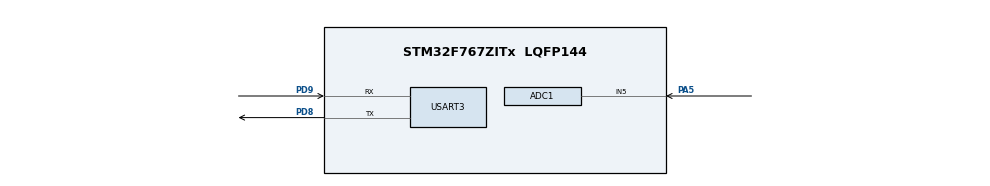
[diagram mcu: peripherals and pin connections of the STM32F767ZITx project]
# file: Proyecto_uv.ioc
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ADC1.Channel-2\#ChannelRegularConversion=ADC_CHANNEL_5
ADC1.NbrOfConversionFlag=1
ADC1.Rank-2\#ChannelRegularConversion=1
ADC1.SamplingTime-2\#ChannelRegularConversion=ADC_SAMPLETIME_3CYCLES
ADC1.master=1
Dma.Request0=USART3_TX
Dma.USART3_TX.0.Direction=DMA_MEMORY_TO_PERIPH
Dma.USART3_TX.0.FIFOMode=DMA_FIFOMODE_DISABLE
Dma.USART3_TX.0.Instance=DMA1_Stream3
Dma.USART3_TX.0.MemDataAlignment=DMA_MDATAALIGN_BYTE
Dma.USART3_TX.0.MemInc=DMA_MINC_ENABLE
Dma.USART3_TX.0.Mode=DMA_NORMAL
Dma.USART3_TX.0.PeriphDataAlignment=DMA_PDATAALIGN_BYTE
Dma.USART3_TX.0.PeriphInc=DMA_PINC_DISABLE
Dma.USART3_TX.0.Priority=DMA_PRIORITY_LOW
FREERTOS.Tasks01=defaultTask,24,128,StartDefaultTask,Default,NULL,Dynamic,NULL,NULL
FREERTOS.configUSE_NEWLIB_REENTRANT=1
Mcu.Family=STM32F7
Mcu.Name=STM32F767ZITx
Mcu.Package=LQFP144
NVIC.DMA1_Stream3_IRQn=true\:5\:0\:false\:false\:true\:true\:false\:true\:true
NVIC.PriorityGroup=NVIC_PRIORITYGROUP_4
NVIC.TIM1_UP_TIM10_IRQn=true\:15\:0\:false\:false\:true\:false\:false\:true\:true
NVIC.TimeBase=TIM1_UP_TIM10_IRQn
NVIC.TimeBaseIP=TIM1
PA5.Signal=ADCx_IN5
PD8.Mode=Asynchronous
PD8.Signal=USART3_TX
PD9.Mode=Asynchronous
PD9.Signal=USART3_RX
ProjectManager.HeapSize=0x200
ProjectManager.StackSize=0x400
ProjectManager.TargetToolchain=STM32CubeIDE
RCC.HSE_VALUE=25000000
RCC.HSI_VALUE=16000000
RCC.LSE_VALUE=32768
RCC.USBFreq_Value=96000000
RCC.VCOOutputFreq_Value=192000000
SH.ADCx_IN5.0=ADC1_IN5,IN5
USART3.VirtualMode-Asynchronous=VM_ASYNC
VP_FREERTOS_VS_CMSIS_V2.Mode=CMSIS_V2
VP_SYS_VS_tim1.Mode=TIM1
board=custom

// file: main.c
/* USER CODE BEGIN Header */
/**
 ******************************************************************************
 * @file           : main.c
 * @brief          : Main program body
 ******************************************************************************
 * @attention
 *
 * Copyright (c) 2022 STMicroelectronics.
 * All rights reserved.
 *
 * This software is licensed under terms that can be found in the LICENSE file
 * in the root directory of this software component.
 * If no LICENSE file comes with this software, it is provided AS-IS.
 *
 ******************************************************************************
 */
/* USER CODE END Header */
#include "main.h"
#include "cmsis_os.h"
#include <stdio.h>
#include <string.h>

ADC_HandleTypeDef hadc1;

UART_HandleTypeDef huart3;
DMA_HandleTypeDef hdma_usart3_tx;

/* Definitions for defaultTask */
osThreadId_t defaultTaskHandle;
const osThreadAttr_t defaultTask_attributes = { .name = "defaultTask",
		.stack_size = 128 * 4, .priority = (osPriority_t) osPriorityNormal, };

void SystemClock_Config(void);
static void MX_GPIO_Init(void);
static void MX_ADC1_Init(void);
static void MX_DMA_Init(void);
static void MX_USART3_UART_Init(void);
void StartDefaultTask(void *argument);

int main(void) {
	/* USER CODE BEGIN 1 */
	float sensorVoltage;
	int sensorValue;
	float sensorResult;
	int buffer;
	char array[100];
	HAL_ADC_Start(&hadc1);
	/* USER CODE END 1 */

	/* MCU Configuration--------------------------------------------------------*/

	/* Reset of all peripherals, Initializes the Flash interface and the Systick. */
	HAL_Init();

	/* Configure the system clock */
	SystemClock_Config();

	/* Initialize all configured peripherals */
	MX_GPIO_Init();
	MX_ADC1_Init();
	MX_DMA_Init();
	MX_USART3_UART_Init();
	/* Init scheduler */
	osKernelInitialize();

	/* Create the thread(s) */
	/* creation of defaultTask */
	defaultTaskHandle = osThreadNew(StartDefaultTask, NULL,
			&defaultTask_attributes);

	/* Start scheduler */
	osKernelStart();

	/* We should never get here as control is now taken by the scheduler */
	/* Infinite loop */
	while (1) {
		HAL_ADC_Start(&hadc1);
		HAL_ADC_PollForConversion(&hadc1, 100);
		sensorVoltage = HAL_ADC_GetValue(&hadc1);
		sensorResult = sensorVoltage / 1024 * 5.0;
		sensorValue = (int) sensorResult;
		HAL_ADC_Stop(&hadc1);

		buffer = sprintf(array, "Solar level %d \r\n", sensorValue);
		HAL_UART_Transmit(&huart3, (uint8_t*) &buffer, 50, 100);

		HAL_Delay(100);

	}
}

void SystemClock_Config(void) {
	RCC_OscInitTypeDef RCC_OscInitStruct = { 0 };
	RCC_ClkInitTypeDef RCC_ClkInitStruct = { 0 };

	/** Configure the main internal regulator output voltage
	 */
	__HAL_RCC_PWR_CLK_ENABLE();
	__HAL_PWR_VOLTAGESCALING_CONFIG(PWR_REGULATOR_VOLTAGE_SCALE3);

	/** Initializes the RCC Oscillators according to the specified parameters
	 * in the RCC_OscInitTypeDef structure.
	 */
	RCC_OscInitStruct.OscillatorType = RCC_OSCILLATORTYPE_HSI;
	RCC_OscInitStruct.HSIState = RCC_HSI_ON;
	RCC_OscInitStruct.HSICalibrationValue = RCC_HSICALIBRATION_DEFAULT;
	RCC_OscInitStruct.PLL.PLLState = RCC_PLL_NONE;
	if (HAL_RCC_OscConfig(&RCC_OscInitStruct) != HAL_OK) {
		Error_Handler();
	}

	/** Initializes the CPU, AHB and APB buses clocks
	 */
	RCC_ClkInitStruct.ClockType = RCC_CLOCKTYPE_HCLK | RCC_CLOCKTYPE_SYSCLK
			| RCC_CLOCKTYPE_PCLK1 | RCC_CLOCKTYPE_PCLK2;
	RCC_ClkInitStruct.SYSCLKSource = RCC_SYSCLKSOURCE_HSI;
	RCC_ClkInitStruct.AHBCLKDivider = RCC_SYSCLK_DIV1;
	RCC_ClkInitStruct.APB1CLKDivider = RCC_HCLK_DIV1;
	RCC_ClkInitStruct.APB2CLKDivider = RCC_HCLK_DIV1;

	if (HAL_RCC_ClockConfig(&RCC_ClkInitStruct, FLASH_LATENCY_0) != HAL_OK) {
		Error_Handler();
	}
}

static void MX_ADC1_Init(void) {

	ADC_ChannelConfTypeDef sConfig = { 0 };

	/** Configure the global features of the ADC (Clock, Resolution, Data Alignment and number of conversion)
	 */
	hadc1.Instance = ADC1;
	hadc1.Init.ClockPrescaler = ADC_CLOCK_SYNC_PCLK_DIV2;
	hadc1.Init.Resolution = ADC_RESOLUTION_12B;
	hadc1.Init.ScanConvMode = ADC_SCAN_DISABLE;
	hadc1.Init.ContinuousConvMode = DISABLE;
	hadc1.Init.DiscontinuousConvMode = DISABLE;
	hadc1.Init.ExternalTrigConvEdge = ADC_EXTERNALTRIGCONVEDGE_NONE;
	hadc1.Init.ExternalTrigConv = ADC_SOFTWARE_START;
	hadc1.Init.DataAlign = ADC_DATAALIGN_RIGHT;
	hadc1.Init.NbrOfConversion = 1;
	hadc1.Init.DMAContinuousRequests = DISABLE;
	hadc1.Init.EOCSelection = ADC_EOC_SINGLE_CONV;
	if (HAL_ADC_Init(&hadc1) != HAL_OK) {
		Error_Handler();
	}

	/** Configure for the selected ADC regular channel its corresponding rank in the sequencer and its sample time.
	 */
	sConfig.Channel = ADC_CHANNEL_5;
	sConfig.Rank = ADC_REGULAR_RANK_1;
	sConfig.SamplingTime = ADC_SAMPLETIME_3CYCLES;
	if (HAL_ADC_ConfigChannel(&hadc1, &sConfig) != HAL_OK) {
		Error_Handler();
	}

}

static void MX_USART3_UART_Init(void) {

	huart3.Instance = USART3;
	huart3.Init.BaudRate = 115200;
	huart3.Init.WordLength = UART_WORDLENGTH_8B;
	huart3.Init.StopBits = UART_STOPBITS_1;
	huart3.Init.Parity = UART_PARITY_NONE;
	huart3.Init.Mode = UART_MODE_TX_RX;
	huart3.Init.HwFlowCtl = UART_HWCONTROL_NONE;
	huart3.Init.OverSampling = UART_OVERSAMPLING_16;
	huart3.Init.OneBitSampling = UART_ONE_BIT_SAMPLE_DISABLE;
	huart3.AdvancedInit.AdvFeatureInit = UART_ADVFEATURE_NO_INIT;
	if (HAL_UART_Init(&huart3) != HAL_OK) {
		Error_Handler();
	}

}

static void MX_DMA_Init(void) {

	/* DMA controller clock enable */
	__HAL_RCC_DMA1_CLK_ENABLE();

	/* DMA interrupt init */
	/* DMA1_Stream3_IRQn interrupt configuration */
	HAL_NVIC_SetPriority(DMA1_Stream3_IRQn, 5, 0);
	HAL_NVIC_EnableIRQ(DMA1_Stream3_IRQn);

}

static void MX_GPIO_Init(void) {

	/* GPIO Ports Clock Enable */
	__HAL_RCC_GPIOA_CLK_ENABLE();
	__HAL_RCC_GPIOD_CLK_ENABLE();

}

void StartDefaultTask(void *argument) {
	for (;;) {
		osDelay(1);
	}
}

void HAL_TIM_PeriodElapsedCallback(TIM_HandleTypeDef *htim) {
	if (htim->Instance == TIM1) {
		HAL_IncTick();
	}
}

void Error_Handler(void) {
	__disable_irq();
	while (1) {
	}
}
